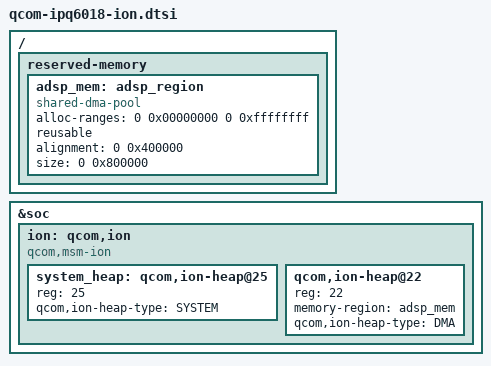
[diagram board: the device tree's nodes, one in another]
/*
 * Copyright (c) 2018-2019, The Linux Foundation. All rights reserved.
 *
 * Permission to use, copy, modify, and/or distribute this software for any
 * purpose with or without fee is hereby granted, provided that the above
 * copyright notice and this permission notice appear in all copies.
 *
 * THE SOFTWARE IS PROVIDED "AS IS" AND THE AUTHOR DISCLAIMS ALL WARRANTIES
 * WITH REGARD TO THIS SOFTWARE INCLUDING ALL IMPLIED WARRANTIES OF
 * MERCHANTABILITY AND FITNESS. IN NO EVENT SHALL THE AUTHOR BE LIABLE FOR
 * ANY SPECIAL, DIRECT, INDIRECT, OR CONSEQUENTIAL DAMAGES OR ANY DAMAGES
 * WHATSOEVER RESULTING FROM LOSS OF USE, DATA OR PROFITS, WHETHER IN AN
 * ACTION OF CONTRACT, NEGLIGENCE OR OTHER TORTIOUS ACTION, ARISING OUT OF
 * OR IN CONNECTION WITH THE USE OR PERFORMANCE OF THIS SOFTWARE.
 */

#if !defined(__IPQ_MEM_PROFILE_256_MB__) && !defined(__IPQ_MEM_PROFILE_512_MB__)
/ {
	reserved-memory {
		#address-cells = <2>;
		#size-cells = <2>;
		ranges;

		adsp_mem: adsp_region {
			compatible = "shared-dma-pool";
			alloc-ranges = <0 0x00000000 0 0xffffffff>;
			reusable;
			alignment = <0 0x400000>;
			size = <0 0x800000>;
		};
	};
};

&soc {
	ion: qcom,ion {
		compatible = "qcom,msm-ion";
		#address-cells = <1>;
		#size-cells = <0>;

		system_heap: qcom,ion-heap@25 {
			reg = <25>;
			qcom,ion-heap-type = "SYSTEM";
		};

		qcom,ion-heap@22 { /* ADSP HEAP */
			reg = <22>;
			memory-region = <&adsp_mem>;
			qcom,ion-heap-type = "DMA";
		};
	};
};
#endif
